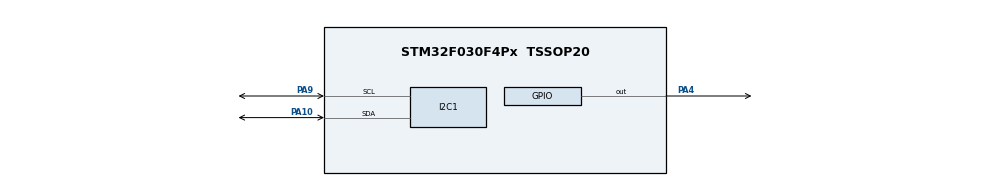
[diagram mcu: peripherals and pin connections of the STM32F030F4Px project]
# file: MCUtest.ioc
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I2C1.Speed=1
I2C1.Timing=0xF000F3FF
Mcu.Family=STM32F0
Mcu.Name=STM32F030F4Px
Mcu.Package=TSSOP20
PA10.Mode=I2C
PA10.Signal=I2C1_SDA
PA4.Signal=GPIO_Output
PA9.Mode=I2C
PA9.Signal=I2C1_SCL
PF0-OSC_IN.Mode=HSE-External-Oscillator
PF0-OSC_IN.Signal=RCC_OSC_IN
PF1-OSC_OUT.Mode=HSE-External-Oscillator
PF1-OSC_OUT.Signal=RCC_OSC_OUT
ProjectManager.HeapSize=0x200
ProjectManager.StackSize=0x400
ProjectManager.TargetToolchain=STM32CubeIDE
RCC.AHBCLKDivider=RCC_SYSCLK_DIV512
RCC.AHBFreq_Value=15625
RCC.APB1Freq_Value=15625
RCC.APB1TimFreq_Value=15625
RCC.HCLKFreq_Value=15625
RCC.SYSCLKSource=RCC_SYSCLKSOURCE_HSE
TIM1.Prescaler=0
VP_TIM1_VS_ClockSourceINT.Mode=Internal
board=custom

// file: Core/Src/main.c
/* USER CODE BEGIN Header */
/**
  ******************************************************************************
  * @file           : main.c
  * @brief          : Main program body
  ******************************************************************************
  * @attention
  *
  * Copyright (c) 2023 STMicroelectronics.
  * All rights reserved.
  *
  * This software is licensed under terms that can be found in the LICENSE file
  * in the root directory of this software component.
  * If no LICENSE file comes with this software, it is provided AS-IS.
  *
  ******************************************************************************
  */
/* USER CODE END Header */
#include "main.h"

void SystemClock_Config(void);
static void MX_GPIO_Init(void);
static void MX_TIM1_Init(void);
static void MX_I2C1_Init(void);

int main(void)
{

  /* MCU Configuration--------------------------------------------------------*/

  /* Reset of all peripherals, Initializes the Flash interface and the Systick. */
  LL_APB1_GRP2_EnableClock(LL_APB1_GRP2_PERIPH_SYSCFG);
  LL_APB1_GRP1_EnableClock(LL_APB1_GRP1_PERIPH_PWR);

  /* SysTick_IRQn interrupt configuration */
  NVIC_SetPriority(SysTick_IRQn, 3);

  /* Configure the system clock */
  SystemClock_Config();

  /* Initialize all configured peripherals */
  MX_GPIO_Init();
  MX_TIM1_Init();
  MX_I2C1_Init();
  /* USER CODE BEGIN 2 */

  LL_I2C_SetSlaveAddr(I2C1, 0b0111100);

  LL_I2C_TransmitData8(I2C1, 0xAE); // Set display OFF

  LL_I2C_TransmitData8(I2C1, 0xD5); // Set Display Clock Divide Ratio / OSC Frequency
  LL_I2C_TransmitData8(I2C1, 0x80); // Display Clock Divide Ratio / OSC Frequency

  LL_I2C_TransmitData8(I2C1, 0xA8); // Set Multiplex Ratio
  LL_I2C_TransmitData8(I2C1, 0x3F); // Multiplex Ratio for 128x64 (64-1)

  LL_I2C_TransmitData8(I2C1, 0xD3); // Set Display Offset
  LL_I2C_TransmitData8(I2C1, 0x00); // Display Offset

  LL_I2C_TransmitData8(I2C1, 0xA3); // Set Display Start Line
  LL_I2C_TransmitData8(I2C1, 0x00); // Set Display Start Line
  LL_I2C_TransmitData8(I2C1, 0x40); // Set Display Start Line

  LL_I2C_TransmitData8(I2C1, 0x8D); // Set Charge Pump
  LL_I2C_TransmitData8(I2C1, 0x14); // Charge Pump (0x10 External, 0x14 Internal DC/DC)
  LL_I2C_TransmitData8(I2C1, 0xAF);

  LL_I2C_TransmitData8(I2C1, 0xA0); // Set Segment Re-Map
  LL_I2C_TransmitData8(I2C1, 0xC0); // Set Com Output Scan Direction

  LL_I2C_TransmitData8(I2C1, 0xDA); // Set COM Hardware Configuration
  LL_I2C_TransmitData8(I2C1, 0x12); // COM Hardware Configuration

  LL_I2C_TransmitData8(I2C1, 0x81); // Set Contrast
  LL_I2C_TransmitData8(I2C1, 0x7F); // Contrast

  LL_I2C_TransmitData8(I2C1, 0xD9); // Set Pre-Charge Period
  LL_I2C_TransmitData8(I2C1, 0x22); // Set Pre-Charge Period (0x22 External, 0xF1 Internal)

  LL_I2C_TransmitData8(I2C1, 0xDB); // Set VCOMH Deselect Level
  LL_I2C_TransmitData8(I2C1, 0x20); // VCOMH Deselect Level

  //LL_I2C_TransmitData8(I2C1, 0xA5); // Set all pixels ON
  LL_I2C_TransmitData8(I2C1, 0xA6); // Set display not inverted
  LL_I2C_TransmitData8(I2C1, 0xAF); // Set display On
  LL_I2C_TransmitData8(I2C1, 0xA5); // Set all pixels ON

  /* USER CODE END 2 */

  /* Infinite loop */
  while (1)
  {

	/* USER CODE BEGIN 3 */
	 if(TIM1->CNT % 650000 <= 32500){
		 LL_GPIO_ResetOutputPin(GPIOA, LL_GPIO_PIN_4);
	 }else{
		 LL_GPIO_SetOutputPin(GPIOA, LL_GPIO_PIN_4);
	 }

  }
  /* USER CODE END 3 */
}

void SystemClock_Config(void)
{
  LL_FLASH_SetLatency(LL_FLASH_LATENCY_0);
  while(LL_FLASH_GetLatency() != LL_FLASH_LATENCY_0)
  {
  }
  LL_RCC_HSE_Enable();

   /* Wait till HSE is ready */
  while(LL_RCC_HSE_IsReady() != 1)
  {

  }
  LL_RCC_HSI_Enable();

   /* Wait till HSI is ready */
  while(LL_RCC_HSI_IsReady() != 1)
  {

  }
  LL_RCC_HSI_SetCalibTrimming(16);
  LL_RCC_SetAHBPrescaler(LL_RCC_SYSCLK_DIV_512);
  LL_RCC_SetAPB1Prescaler(LL_RCC_APB1_DIV_1);
  LL_RCC_SetSysClkSource(LL_RCC_SYS_CLKSOURCE_HSE);

   /* Wait till System clock is ready */
  while(LL_RCC_GetSysClkSource() != LL_RCC_SYS_CLKSOURCE_STATUS_HSE)
  {

  }
  LL_Init1msTick(15625);
  LL_SetSystemCoreClock(15625);
  LL_RCC_SetI2CClockSource(LL_RCC_I2C1_CLKSOURCE_HSI);
}

static void MX_I2C1_Init(void)
{

  LL_I2C_InitTypeDef I2C_InitStruct = {0};

  LL_GPIO_InitTypeDef GPIO_InitStruct = {0};

  LL_AHB1_GRP1_EnableClock(LL_AHB1_GRP1_PERIPH_GPIOA);
  /**I2C1 GPIO Configuration
  PA9   ------> I2C1_SCL
  PA10   ------> I2C1_SDA
  */
  GPIO_InitStruct.Pin = LL_GPIO_PIN_9;
  GPIO_InitStruct.Mode = LL_GPIO_MODE_ALTERNATE;
  GPIO_InitStruct.Speed = LL_GPIO_SPEED_FREQ_HIGH;
  GPIO_InitStruct.OutputType = LL_GPIO_OUTPUT_OPENDRAIN;
  GPIO_InitStruct.Pull = LL_GPIO_PULL_UP;
  GPIO_InitStruct.Alternate = LL_GPIO_AF_4;
  LL_GPIO_Init(GPIOA, &GPIO_InitStruct);

  GPIO_InitStruct.Pin = LL_GPIO_PIN_10;
  GPIO_InitStruct.Mode = LL_GPIO_MODE_ALTERNATE;
  GPIO_InitStruct.Speed = LL_GPIO_SPEED_FREQ_HIGH;
  GPIO_InitStruct.OutputType = LL_GPIO_OUTPUT_OPENDRAIN;
  GPIO_InitStruct.Pull = LL_GPIO_PULL_UP;
  GPIO_InitStruct.Alternate = LL_GPIO_AF_4;
  LL_GPIO_Init(GPIOA, &GPIO_InitStruct);

  /* Peripheral clock enable */
  LL_APB1_GRP1_EnableClock(LL_APB1_GRP1_PERIPH_I2C1);

  /** I2C Initialization
  */
  LL_I2C_DisableOwnAddress2(I2C1);
  LL_I2C_DisableGeneralCall(I2C1);
  LL_I2C_EnableClockStretching(I2C1);
  I2C_InitStruct.PeripheralMode = LL_I2C_MODE_I2C;
  I2C_InitStruct.Timing = 0xF000F3FF;
  I2C_InitStruct.AnalogFilter = LL_I2C_ANALOGFILTER_ENABLE;
  I2C_InitStruct.DigitalFilter = 0;
  I2C_InitStruct.OwnAddress1 = 0;
  I2C_InitStruct.TypeAcknowledge = LL_I2C_ACK;
  I2C_InitStruct.OwnAddrSize = LL_I2C_OWNADDRESS1_7BIT;
  LL_I2C_Init(I2C1, &I2C_InitStruct);
  LL_I2C_EnableAutoEndMode(I2C1);
  LL_I2C_SetOwnAddress2(I2C1, 0, LL_I2C_OWNADDRESS2_NOMASK);
  /* USER CODE BEGIN I2C1_Init 2 */
  LL_I2C_Enable(I2C1);
  /* USER CODE END I2C1_Init 2 */

}

static void MX_TIM1_Init(void)
{

  LL_TIM_InitTypeDef TIM_InitStruct = {0};

  /* Peripheral clock enable */
  LL_APB1_GRP2_EnableClock(LL_APB1_GRP2_PERIPH_TIM1);

  TIM_InitStruct.Prescaler = 0;
  TIM_InitStruct.CounterMode = LL_TIM_COUNTERMODE_UP;
  TIM_InitStruct.Autoreload = 65535;
  TIM_InitStruct.ClockDivision = LL_TIM_CLOCKDIVISION_DIV1;
  TIM_InitStruct.RepetitionCounter = 0;
  LL_TIM_Init(TIM1, &TIM_InitStruct);
  LL_TIM_DisableARRPreload(TIM1);
  LL_TIM_SetClockSource(TIM1, LL_TIM_CLOCKSOURCE_INTERNAL);
  LL_TIM_SetTriggerOutput(TIM1, LL_TIM_TRGO_RESET);
  LL_TIM_DisableMasterSlaveMode(TIM1);
  /* USER CODE BEGIN TIM1_Init 2 */
  LL_TIM_EnableCounter(TIM1);
  /* USER CODE END TIM1_Init 2 */

}

static void MX_GPIO_Init(void)
{
  LL_GPIO_InitTypeDef GPIO_InitStruct = {0};

  /* GPIO Ports Clock Enable */
  LL_AHB1_GRP1_EnableClock(LL_AHB1_GRP1_PERIPH_GPIOF);
  LL_AHB1_GRP1_EnableClock(LL_AHB1_GRP1_PERIPH_GPIOA);

  /**/
  LL_GPIO_ResetOutputPin(GPIOA, LL_GPIO_PIN_4);

  /**/
  GPIO_InitStruct.Pin = LL_GPIO_PIN_4;
  GPIO_InitStruct.Mode = LL_GPIO_MODE_OUTPUT;
  GPIO_InitStruct.Speed = LL_GPIO_SPEED_FREQ_LOW;
  GPIO_InitStruct.OutputType = LL_GPIO_OUTPUT_PUSHPULL;
  GPIO_InitStruct.Pull = LL_GPIO_PULL_NO;
  LL_GPIO_Init(GPIOA, &GPIO_InitStruct);

}

void Error_Handler(void)
{
  __disable_irq();
  while (1)
  {
  }
}
